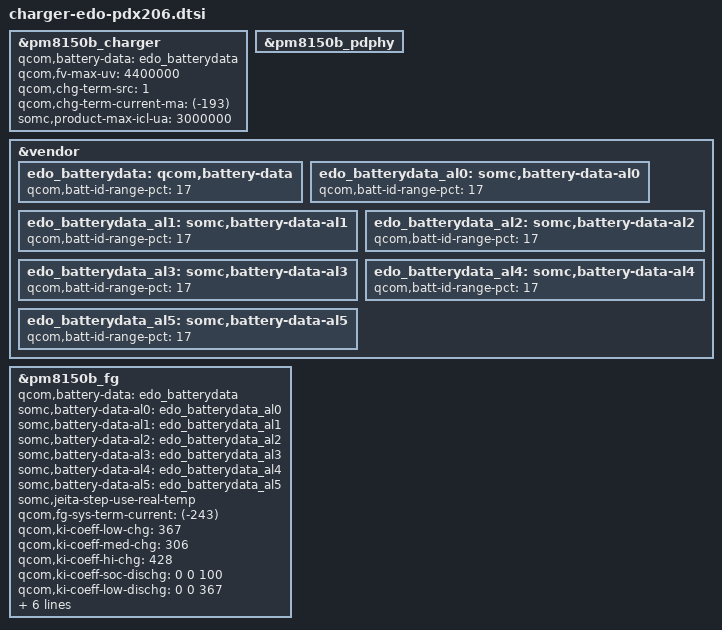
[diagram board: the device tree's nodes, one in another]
/* Copyright (c) 2015-2019, The Linux Foundation. All rights reserved.
 *
 * This program is free software; you can redistribute it and/or modify
 * it under the terms of the GNU General Public License version 2 and
 * only version 2 as published by the Free Software Foundation.
 *
 * This program is distributed in the hope that it will be useful,
 * but WITHOUT ANY WARRANTY; without even the implied warranty of
 * MERCHANTABILITY or FITNESS FOR A PARTICULAR PURPOSE.  See the
 * GNU General Public License for more details.
 */

&pm8150b_charger {
	qcom,battery-data = <&edo_batterydata>;
	qcom,fv-max-uv = <4400000>;
	qcom,chg-term-src = <1>;
	qcom,chg-term-current-ma = <(-193)>;
	somc,product-max-icl-ua = <3000000>;
};

&pm8150b_pdphy {
};

&vendor {
	edo_batterydata: qcom,battery-data {
		qcom,batt-id-range-pct = <17>;
		#include "fg-gen4-batterydata-edo-reference.dtsi"
	};
	edo_batterydata_al0: somc,battery-data-al0 {
		qcom,batt-id-range-pct = <17>;
		#include "fg-gen4-batterydata-pdx206-tdk-4400mv.dtsi"
	};
	edo_batterydata_al1: somc,battery-data-al1 {
		qcom,batt-id-range-pct = <17>;
		#include "fg-gen4-batterydata-pdx206-tdk-4370mv.dtsi"
	};
	edo_batterydata_al2: somc,battery-data-al2 {
		qcom,batt-id-range-pct = <17>;
		#include "fg-gen4-batterydata-pdx206-tdk-4340mv.dtsi"
	};
	edo_batterydata_al3: somc,battery-data-al3 {
		qcom,batt-id-range-pct = <17>;
		#include "fg-gen4-batterydata-pdx206-tdk-4300mv.dtsi"
	};
	edo_batterydata_al4: somc,battery-data-al4 {
		qcom,batt-id-range-pct = <17>;
		#include "fg-gen4-batterydata-pdx206-tdk-4250mv.dtsi"
	};
	edo_batterydata_al5: somc,battery-data-al5 {
		qcom,batt-id-range-pct = <17>;
		#include "fg-gen4-batterydata-pdx206-tdk-4200mv.dtsi"
	};
};

&pm8150b_fg {
	qcom,battery-data = <&edo_batterydata>;
	somc,battery-data-al0 = <&edo_batterydata_al0>;
	somc,battery-data-al1 = <&edo_batterydata_al1>;
	somc,battery-data-al2 = <&edo_batterydata_al2>;
	somc,battery-data-al3 = <&edo_batterydata_al3>;
	somc,battery-data-al4 = <&edo_batterydata_al4>;
	somc,battery-data-al5 = <&edo_batterydata_al5>;
	somc,jeita-step-use-real-temp;
	qcom,fg-sys-term-current = <(-243)>;
	qcom,ki-coeff-low-chg = <367>;
	qcom,ki-coeff-med-chg = <306>;
	qcom,ki-coeff-hi-chg = <428>;
	qcom,ki-coeff-soc-dischg = <0 0 100>;
	qcom,ki-coeff-low-dischg = <0 0 367>;
	qcom,ki-coeff-med-dischg = <0 0 306>;
	qcom,ki-coeff-hi-dischg = <0 0 428>;
	qcom,ki-coeff-chg-low-med-thresh-ma = <63>;
	qcom,ki-coeff-chg-med-hi-thresh-ma = <500>;
	qcom,ki-coeff-dischg-low-med-thresh-ma = <63>;
	qcom,ki-coeff-dischg-med-hi-thresh-ma = <500>;
};
